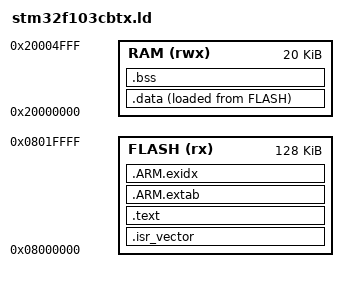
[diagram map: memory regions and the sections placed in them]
ENTRY(Reset_Handler)

MEMORY
{
    FLASH (rx)  : ORIGIN = 0x08000000, LENGTH = 128K
    RAM   (rwx) : ORIGIN = 0x20000000, LENGTH = 20K
}

_estack = ORIGIN(RAM) + LENGTH(RAM);
_minimum_stack_size = 0x400;

SECTIONS
{
    .isr_vector :
    {
        . = ALIGN(4);
        KEEP(*(.isr_vector))
        . = ALIGN(4);
    } > FLASH

    .text :
    {
        . = ALIGN(4);
        *(.text*)
        *(.rodata*)
        . = ALIGN(4);
        _etext = .;
    } > FLASH

    .ARM.extab :
    {
        *(.ARM.extab* .gnu.linkonce.armextab.*)
    } > FLASH

    .ARM.exidx :
    {
        __exidx_start = .;
        *(.ARM.exidx*)
        __exidx_end = .;
    } > FLASH

    .data :
    {
        . = ALIGN(4);
        _sdata = .;
        *(.data*)
        . = ALIGN(4);
        _edata = .;
    } > RAM AT > FLASH
    _sidata = LOADADDR(.data);

    .bss (NOLOAD) :
    {
        . = ALIGN(4);
        _sbss = .;
        *(.bss*)
        *(COMMON)
        . = ALIGN(4);
        _ebss = .;
    } > RAM

    _end = _ebss;
    _stack_limit = _estack - _minimum_stack_size;
    ASSERT(_ebss <= _stack_limit, "RAM overflow: less than 1 KiB remains for the stack")

    .ARM.attributes 0 :
    {
        KEEP(*(.ARM.attributes))
    }

    /DISCARD/ :
    {
        *(.comment)
        *(.note*)
    }
}
